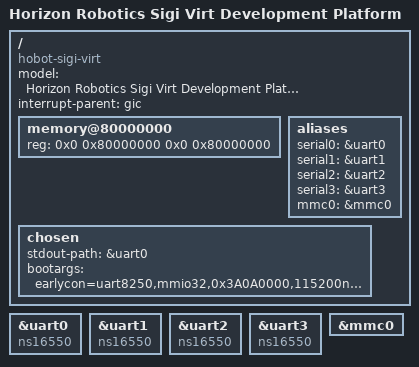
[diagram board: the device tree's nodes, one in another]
// SPDX-License-Identifier: (GPL-2.0+ OR MIT)
/*
 * Horizon Robotics Sigi Virt device tree
 *
 * Copyright (c) 2023 Beijing Horizon Robotics Co., Ltd
 */

/dts-v1/;

#include "hobot-sigie.dtsi"
/ {
    compatible = "hobot-sigi-virt";
    model = "Horizon Robotics Sigi Virt Development Platform";
    #address-cells = <2>;
    #size-cells = <2>;
    interrupt-parent = <&gic>;

    memory@80000000 {
        reg = <0x0 0x80000000 0x0 0x80000000>;
        device_type = "memory";
    };

    aliases {
        serial0 = &uart0;
        serial1 = &uart1;
        serial2 = &uart2;
        serial3 = &uart3;
        mmc0 = &mmc0;
    };

    chosen {
        stdout-path = &uart0;
        bootargs = "earlycon=uart8250,mmio32,0x3A0A0000,115200n8 console=ttyS0,115200 rdinit=/sbin/init root=/dev/mmcblk0p7 rw rootwait debug";
    };
};

&uart0 {
    compatible = "ns16550";
    status = "okay";
};

&uart1 {
    compatible = "ns16550";
    status = "okay";
};

&uart2 {
    compatible = "ns16550";
    status = "okay";
};

&uart3 {
    compatible = "ns16550";
    status = "okay";
};

&mmc0 {
    status = "okay";
};
